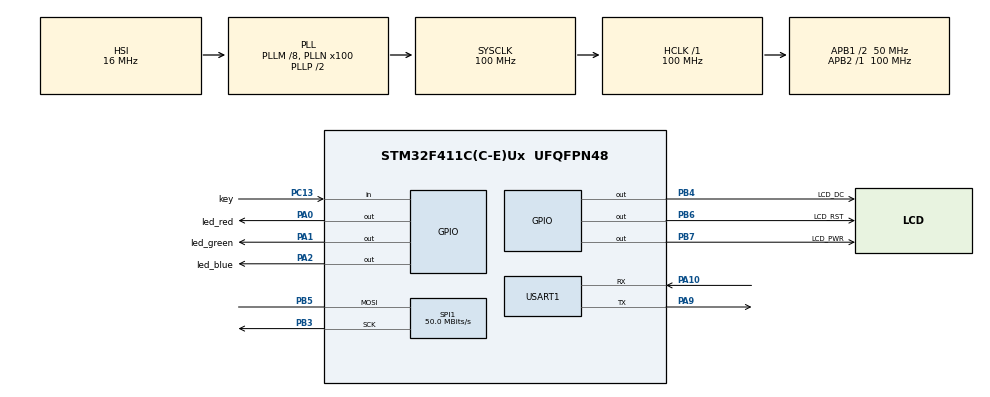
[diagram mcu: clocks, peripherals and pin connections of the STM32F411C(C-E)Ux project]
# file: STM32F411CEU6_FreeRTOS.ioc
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FREERTOS.Tasks01=defaultTask,24,128,StartDefaultTask,Default,NULL,Dynamic,NULL,NULL
Mcu.Family=STM32F4
Mcu.Name=STM32F411C(C-E)Ux
Mcu.Package=UFQFPN48
NVIC.PriorityGroup=NVIC_PRIORITYGROUP_4
NVIC.TIM1_BRK_TIM9_IRQn=true\:5\:0\:false\:false\:true\:true\:true\:true\:true
NVIC.TIM1_UP_TIM10_IRQn=true\:0\:0\:true\:false\:true\:false\:false\:true\:true
NVIC.TIM5_IRQn=true\:5\:0\:false\:false\:true\:true\:true\:true\:true
NVIC.TimeBase=TIM1_UP_TIM10_IRQn
NVIC.TimeBaseIP=TIM10
PA0-WKUP.GPIO_Label=led_red
PA0-WKUP.GPIO_PuPd=GPIO_PULLUP
PA0-WKUP.PinState=GPIO_PIN_SET
PA0-WKUP.Signal=GPIO_Output
PA1.GPIO_Label=led_green
PA1.GPIO_PuPd=GPIO_PULLUP
PA1.Signal=GPIO_Output
PA10.Mode=Asynchronous
PA10.Signal=USART1_RX
PA13.Mode=Serial_Wire
PA13.Signal=SYS_JTMS-SWDIO
PA14.Mode=Serial_Wire
PA14.Signal=SYS_JTCK-SWCLK
PA2.GPIO_Label=led_blue
PA2.GPIO_PuPd=GPIO_PULLUP
PA2.PinState=GPIO_PIN_SET
PA2.Signal=GPIO_Output
PA9.Mode=Asynchronous
PA9.Signal=USART1_TX
PB3.Mode=Simplex_Bidirectional_Master
PB3.Signal=SPI1_SCK
PB4.GPIO_Label=LCD_DC
PB4.Signal=GPIO_Output
PB5.Mode=Simplex_Bidirectional_Master
PB5.Signal=SPI1_MOSI
PB6.GPIO_Label=LCD_RST
PB6.Signal=GPIO_Output
PB7.GPIO_Label=LCD_PWR
PB7.Signal=GPIO_Output
PC13-ANTI_TAMP.GPIO_Label=key
PC13-ANTI_TAMP.GPIO_PuPd=GPIO_PULLUP
PC13-ANTI_TAMP.Signal=GPIO_Input
PH0\ -\ OSC_IN.Mode=HSE-External-Oscillator
PH0\ -\ OSC_IN.Signal=RCC_OSC_IN
PH1\ -\ OSC_OUT.Mode=HSE-External-Oscillator
PH1\ -\ OSC_OUT.Signal=RCC_OSC_OUT
ProjectManager.HeapSize=0x200
ProjectManager.StackSize=0x400
ProjectManager.TargetToolchain=MDK-ARM V5.27
RCC.48MHZClocksFreq_Value=50000000
RCC.AHBFreq_Value=100000000
RCC.APB1CLKDivider=RCC_HCLK_DIV2
RCC.APB1Freq_Value=50000000
RCC.APB1TimFreq_Value=100000000
RCC.APB2Freq_Value=100000000
RCC.APB2TimFreq_Value=100000000
RCC.CortexFreq_Value=100000000
RCC.HCLKFreq_Value=100000000
RCC.HSE_VALUE=12000000
RCC.HSI_VALUE=16000000
RCC.LSE_VALUE=32768
RCC.PLLM=8
RCC.PLLN=100
RCC.SYSCLKFreq_VALUE=100000000
RCC.SYSCLKSource=RCC_SYSCLKSOURCE_PLLCLK
RCC.VCOOutputFreq_Value=200000000
SPI1.CLKPhase=SPI_PHASE_2EDGE
SPI1.CLKPolarity=SPI_POLARITY_HIGH
SPI1.CalculateBaudRate=50.0 MBits/s
SPI1.Direction=SPI_DIRECTION_1LINE
SPI1.Mode=SPI_MODE_MASTER
SPI1.VirtualType=VM_MASTER
TIM5.Period=10000-1
TIM5.Prescaler=1000-1
TIM9.Period=10000-1
TIM9.Prescaler=1000-1
USART1.VirtualMode=VM_ASYNC
VP_FREERTOS_VS_CMSIS_V2.Mode=CMSIS_V2
VP_SYS_VS_tim10.Mode=TIM10
VP_TIM5_VS_ClockSourceINT.Mode=Internal
VP_TIM9_VS_ClockSourceINT.Mode=Internal
board=custom

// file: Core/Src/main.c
/* USER CODE BEGIN Header */
/**
  ******************************************************************************
  * @file           : main.c
  * @brief          : Main program body
  ******************************************************************************
  * @attention
  *
  * Copyright (c) 2023 STMicroelectronics.
  * All rights reserved.
  *
  * This software is licensed under terms that can be found in the LICENSE file
  * in the root directory of this software component.
  * If no LICENSE file comes with this software, it is provided AS-IS.
  *
  ******************************************************************************
  */
/* USER CODE END Header */
#include "main.h"
#include "cmsis_os.h"
#include "spi.h"
#include "tim.h"
#include "usart.h"
#include "gpio.h"

void SystemClock_Config(void);
void MX_FREERTOS_Init(void);

int main(void)
{

  /* MCU Configuration--------------------------------------------------------*/

  /* Reset of all peripherals, Initializes the Flash interface and the Systick. */
  HAL_Init();

  /* Configure the system clock */
  SystemClock_Config();

  /* Initialize all configured peripherals */
  MX_GPIO_Init();
  MX_USART1_UART_Init();
  MX_SPI1_Init();
  MX_TIM5_Init();
  MX_TIM9_Init();
  /* USER CODE BEGIN 2 */
	LCD_Init();
	LCD_Clear(BLACK);
	LCD_ShowString(0, 0*32, strlen("FreeRTOS_DEMO4")*16, 32, 32, "FreeRTOS_DEMO4");
	LCD_ShowString(0, 1*32, strlen("Uart1 Printf ... ")*12, 24, 24, "Uart1 Printf ... ");
	printf("实验内容为每隔5秒自动的开启关闭中断 \r\n");

	HAL_TIM_Base_Start_IT(&htim5);
	HAL_TIM_Base_Start_IT(&htim9);
  /* USER CODE END 2 */

  /* Init scheduler */
  osKernelInitialize();  /* Call init function for freertos objects (in freertos.c) */
  MX_FREERTOS_Init();

  /* Start scheduler */
  osKernelStart();

  /* We should never get here as control is now taken by the scheduler */
  /* Infinite loop */
  while (1)
  {

  }
}

void SystemClock_Config(void)
{
  RCC_OscInitTypeDef RCC_OscInitStruct = {0};
  RCC_ClkInitTypeDef RCC_ClkInitStruct = {0};

  /** Configure the main internal regulator output voltage
  */
  __HAL_RCC_PWR_CLK_ENABLE();
  __HAL_PWR_VOLTAGESCALING_CONFIG(PWR_REGULATOR_VOLTAGE_SCALE1);

  /** Initializes the RCC Oscillators according to the specified parameters
  * in the RCC_OscInitTypeDef structure.
  */
  RCC_OscInitStruct.OscillatorType = RCC_OSCILLATORTYPE_HSI;
  RCC_OscInitStruct.HSIState = RCC_HSI_ON;
  RCC_OscInitStruct.HSICalibrationValue = RCC_HSICALIBRATION_DEFAULT;
  RCC_OscInitStruct.PLL.PLLState = RCC_PLL_ON;
  RCC_OscInitStruct.PLL.PLLSource = RCC_PLLSOURCE_HSI;
  RCC_OscInitStruct.PLL.PLLM = 8;
  RCC_OscInitStruct.PLL.PLLN = 100;
  RCC_OscInitStruct.PLL.PLLP = RCC_PLLP_DIV2;
  RCC_OscInitStruct.PLL.PLLQ = 4;
  if (HAL_RCC_OscConfig(&RCC_OscInitStruct) != HAL_OK)
  {
    Error_Handler();
  }

  /** Initializes the CPU, AHB and APB buses clocks
  */
  RCC_ClkInitStruct.ClockType = RCC_CLOCKTYPE_HCLK|RCC_CLOCKTYPE_SYSCLK
                              |RCC_CLOCKTYPE_PCLK1|RCC_CLOCKTYPE_PCLK2;
  RCC_ClkInitStruct.SYSCLKSource = RCC_SYSCLKSOURCE_PLLCLK;
  RCC_ClkInitStruct.AHBCLKDivider = RCC_SYSCLK_DIV1;
  RCC_ClkInitStruct.APB1CLKDivider = RCC_HCLK_DIV2;
  RCC_ClkInitStruct.APB2CLKDivider = RCC_HCLK_DIV1;

  if (HAL_RCC_ClockConfig(&RCC_ClkInitStruct, FLASH_LATENCY_3) != HAL_OK)
  {
    Error_Handler();
  }
}

void HAL_TIM_PeriodElapsedCallback(TIM_HandleTypeDef *htim)
{
  if (htim->Instance == TIM10) {
    HAL_IncTick();
  }
  /* USER CODE BEGIN Callback 1 */
	if(htim->Instance == TIM5)
	{
		printf("TIM5 --- 4   uwtick-- %d\r\n",uwTick);
	}
	if(htim->Instance == TIM9)
	{
		printf("TIM9 --- 9\r\n");
	}
  /* USER CODE END Callback 1 */
}

void Error_Handler(void)
{
  __disable_irq();
  while (1)
  {
  }
}
